# DA1469x register map
Vendor: Dialog; Series: DA1469x; File version: 1.2
CPU: CM33 r1p0, little endian, no MPU, FPU, 3 interrupt priority bits
Registers are 32-bit, read-write, reset 0x0 unless marked. A register's access mark holds for its fields unless they carry their own. Offsets are from the block's base; [hi:lo] are bit positions; {n}, {i} and the like mark numbered series.

## TIMER — TIMER registers
Base 0x50010200
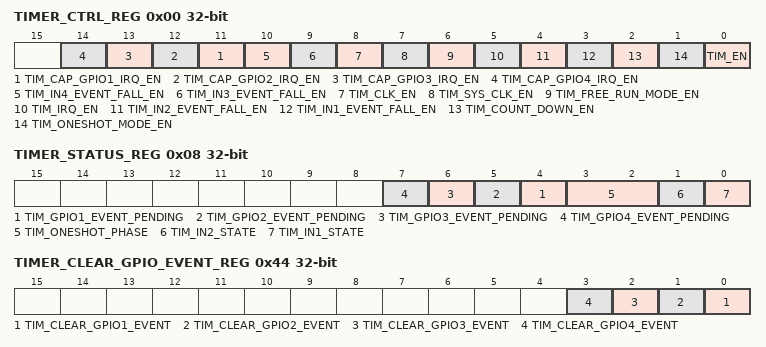
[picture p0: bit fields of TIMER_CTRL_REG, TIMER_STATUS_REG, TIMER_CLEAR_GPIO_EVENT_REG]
0x00 TIMER_CTRL_REG — Timer control register
  [n+10] TIM_CAP_GPIO{n}_IRQ_EN (n=1..4) — 0 = Event on GPIO{n} does not create a CAPTIM interrrupt 1 = Event on GPIO{n} creates a CAPTIM interrrupt
  [10] TIM_IN4_EVENT_FALL_EN — Event input 4 edge type 1 = falling edge 0 = rising edge
  [9] TIM_IN3_EVENT_FALL_EN — Event input 3 edge type 1 = falling edge 0 = rising edge
  [8] TIM_CLK_EN — Timer clock enable 1 = clock enabled 0 = clock disabled
  [7] TIM_SYS_CLK_EN — Select clock 1 = Timer uses the DIVN clock 0 = Timer uses the lp clock
  [6] TIM_FREE_RUN_MODE_EN — Valid when timer counts up, if it is '1' timer does not zero when reaches to reload value. it becomes zero only when it reaches the max value.
  [5] TIM_IRQ_EN — Interrupt mask 1 = timer IRQ is unmasked 0 = timer IRQ is masked
  [4] TIM_IN2_EVENT_FALL_EN — Event input 2 edge type 1 = falling edge 0 = rising edge
  [3] TIM_IN1_EVENT_FALL_EN — Event input 1 edge type 1 = falling edge 0 = rising edge
  [2] TIM_COUNT_DOWN_EN — Timer count direction 1 = down 0 = up
  [1] TIM_ONESHOT_MODE_EN — Timer mode 1 = One shot enabled 0 = Counter enabled
  [0] TIM_EN — Timer enable 1 = On 0 = Off
0x04 TIMER_TIMER_VAL_REG — Timer counter value
  [23:0] TIM_TIMER_VALUE ro — Gives the current timer value
0x08 TIMER_STATUS_REG — Timer status register
  [n+3] TIM_GPIO{n}_EVENT_PENDING ro (n=1..4) — When 1, GPIO{n} event is pending.
  [3:2] TIM_ONESHOT_PHASE ro — OneShot phase 0 = Wait for event 1 = Delay phase 2 = Start Shot 3 = Shot phase
  [1] TIM_IN2_STATE ro — Gives the logic level of the IN1
  [0] TIM_IN1_STATE ro — Gives the logic level of the IN2
0x0C TIMER_GPIO1_CONF_REG — Timer gpio1 selection
  [5:0] TIM_GPIO1_CONF — Select one of the 32 GPIOs as IN1, Valid value 0-32. 1 for the first gpio, 32 for the last gpio. 0 Disable input
0x10 TIMER_GPIO2_CONF_REG — Timer gpio2 selection
  [5:0] TIM_GPIO2_CONF — Select one of the 32 GPIOs as IN2, Valid value 0-32. 1 for the first gpio, 32 for the last gpio. 0 Disable input
0x14 TIMER_RELOAD_REG — Timer reload value and Delay in shot mode
  [23:0] TIM_RELOAD — Reload or max value in timer mode, Delay phase duration in oneshot mode. Actual delay is the register value plus synchronization time (3 clock cycles)
0x18 TIMER_SHOTWIDTH_REG — Timer Shot duration in shot mode
  [23:0] TIM_SHOTWIDTH — Shot phase duration in oneshot mode
0x1C TIMER_PRESCALER_REG — Timer prescaler value
  [4:0] TIM_PRESCALER — Defines the timer count frequency. CLOCK frequency / (TIM_PRESCALER+1)
0x20 TIMER_CAPTURE_GPIO1_REG — Timer value for event on GPIO1
  [23:0] TIM_CAPTURE_GPIO1 ro — Gives the Capture time for event on GPIO1
0x24 TIMER_CAPTURE_GPIO2_REG — Timer value for event on GPIO2
  [23:0] TIM_CAPTURE_GPIO2 ro — Gives the Capture time for event on GPIO2
0x28 TIMER_PRESCALER_VAL_REG — Timer prescaler counter valuew
  [4:0] TIM_PRESCALER_VAL ro — Gives the current prescaler counter value
0x2C TIMER_PWM_FREQ_REG — Timer pwm frequency register
  [15:0] TIM_PWM_FREQ — Defines the PWM frequency. Timer clock frequency / (TIM_PWM_FREQ+1) Timer clock is clock after prescaler
0x30 TIMER_PWM_DC_REG — Timer pwm dc register
  [15:0] TIM_PWM_DC — Defines the PWM duty cycle. TIM_PWM_DC / ( TIM_PWM_FREQ+1)
0x34 TIMER_GPIO3_CONF_REG — Timer gpio3 selection
  [5:0] TIM_GPIO3_CONF — Select one of the 32 GPIOs as IN3, Valid value 0-32. 1 for the first gpio, 32 for the last gpio. 0 Disable input
0x38 TIMER_GPIO4_CONF_REG — Timer gpio4 selection
  [5:0] TIM_GPIO4_CONF — Select one of the 32 GPIOs as IN4, Valid value 0-32. 1 for the first gpio, 32 for the last gpio. 0 Disable input
0x3C TIMER_CAPTURE_GPIO3_REG — Timer value for event on GPIO1
  [23:0] TIM_CAPTURE_GPIO3 ro — Gives the Capture time for event on GPIO3
0x40 TIMER_CAPTURE_GPIO4_REG — Timer value for event on GPIO1
  [23:0] TIM_CAPTURE_GPIO4 ro — Gives the Capture time for event on GPIO4
0x44 TIMER_CLEAR_GPIO_EVENT_REG — Timer clear gpio event register
  [n-1] TIM_CLEAR_GPIO{n}_EVENT wo (n=1..4) — 1 = Clear GPIO{n} event. Return always 0
0x48 TIMER_CLEAR_IRQ_REG — Timer clear interrupt
  [0] TIM_CLEAR_IRQ wo — Write any value clear interrupt

## TIMER2 — TIMER2 registers
Base 0x50010300
Registers as TIMER (with TIMER read as TIMER2), without TIMER_TIMER_VAL_REG, TIMER_GPIO3_CONF_REG, TIMER_GPIO4_CONF_REG, TIMER_CAPTURE_GPIO3_REG, TIMER_CAPTURE_GPIO4_REG, TIMER_CLEAR_GPIO_EVENT_REG, TIMER_CLEAR_IRQ_REG; these are added or differ:
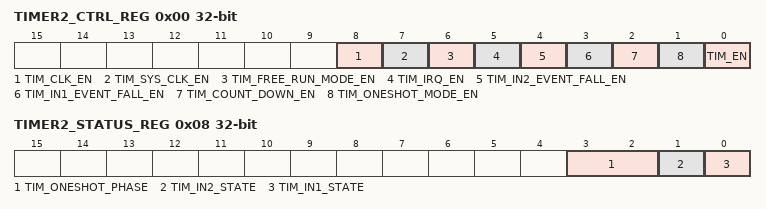
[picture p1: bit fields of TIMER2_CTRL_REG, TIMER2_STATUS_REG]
0x00 TIMER2_CTRL_REG — Timer control register
  [8] TIM_CLK_EN — Timer clock enable 1 = clock enabled 0 = clock disabled
  [7] TIM_SYS_CLK_EN — Select clock 1 = Timer uses the DIVN clock 0 = Timer uses the lp clock
  [6] TIM_FREE_RUN_MODE_EN — Valid when timer counts up, if it is '1' timer does not zero when reaches to reload value. it becomes zero only when it reaches the max value.
  [5] TIM_IRQ_EN — Interrupt mask 1 = timer IRQ is unmasked 0 = timer IRQ is masked
  [4] TIM_IN2_EVENT_FALL_EN — Event input 2 edge type 1 = falling edge 0 = rising edge
  [3] TIM_IN1_EVENT_FALL_EN — Event input 1 edge type 1 = falling edge 0 = rising edge
  [2] TIM_COUNT_DOWN_EN — Timer count direction 1 = down 0 = up
  [1] TIM_ONESHOT_MODE_EN — Timer mode 1 = One shot enabled 0 = Counter enabled
  [0] TIM_EN — Timer enable 1 = On 0 = Off
0x04 TIMER2_TIMER_VAL_REG — Timer counter value
  [23:0] TIM_TIMER_VALUE ro — Gives the current timer value
0x08 TIMER2_STATUS_REG — Timer status register
  [3:2] TIM_ONESHOT_PHASE ro — OneShot phase 0 = Wait for event 1 = Delay phase 2 = Start Shot 3 = Shot phase
  [1] TIM_IN2_STATE ro — Gives the logic level of the IN1
  [0] TIM_IN1_STATE ro — Gives the logic level of the IN2
0x34 TIMER2_CLEAR_IRQ_REG — Timer clear interrupt
  [0] TIM_CLEAR_IRQ wo — Write any value clear interrupt

## TIMER3 — TIMER3 registers
Base 0x50040A00
Registers as TIMER2 (with TIMER2 read as TIMER3), without TIMER2_SHOTWIDTH_REG; these are added or differ:
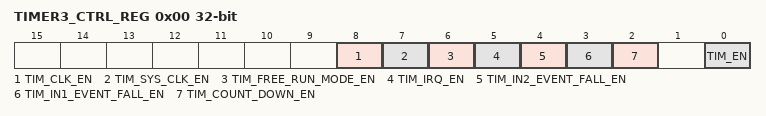
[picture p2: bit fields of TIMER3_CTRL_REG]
0x00 TIMER3_CTRL_REG — Timer control register
  [8] TIM_CLK_EN — Timer clock enable 1 = clock enabled 0 = clock disabled
  [7] TIM_SYS_CLK_EN — Select clock 1 = Timer uses the DIVN clock 0 = Timer uses the lp clock
  [6] TIM_FREE_RUN_MODE_EN — Valid when timer counts up, if it is '1' timer does not zero when reaches to reload value. it becomes zero only when it reaches the max value.
  [5] TIM_IRQ_EN — Interrupt mask 1 = timer IRQ is unmasked 0 = timer IRQ is masked
  [4] TIM_IN2_EVENT_FALL_EN — Event input 2 edge type 1 = falling edge 0 = rising edge
  [3] TIM_IN1_EVENT_FALL_EN — Event input 1 edge type 1 = falling edge 0 = rising edge
  [2] TIM_COUNT_DOWN_EN — Timer count direction 1 = down 0 = up
  [0] TIM_EN — Timer enable 1 = On 0 = Off
0x14 TIMER3_RELOAD_REG — Timer reload value and Delay in shot mode
  [23:0] TIM_RELOAD — Reload or max value in timer mode. Actual delay is the register value plus synchronization time (3 clock cycles)

## TIMER4 — TIMER4 registers
Base 0x50040B00
Registers as TIMER3 (with TIMER3 read as TIMER4).
